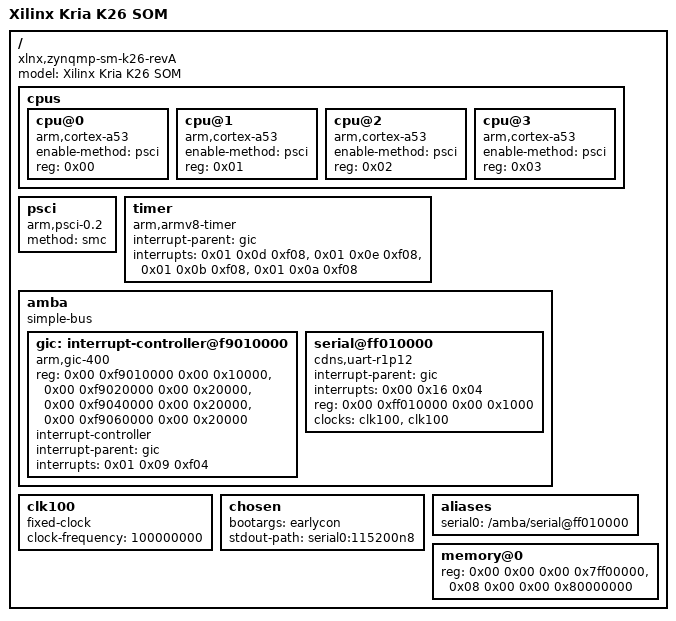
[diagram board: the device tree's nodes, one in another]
/dts-v1/;

/ {
    compatible = "xlnx,zynqmp-sm-k26-revA\0xlnx,zynqmp-sm-k26\0xlnx,zynqmp";
    #address-cells = <0x02>;
    #size-cells = <0x02>;
    model = "Xilinx Kria K26 SOM";

    cpus {
        #address-cells = <0x01>;
        #size-cells = <0x00>;

        cpu@0 {
            compatible = "arm,cortex-a53\0arm,armv8";
            device_type = "cpu";
            enable-method = "psci";
            reg = <0x00>;
        };

        cpu@1 {
            compatible = "arm,cortex-a53\0arm,armv8";
            device_type = "cpu";
            enable-method = "psci";
            reg = <0x01>;
        };

        cpu@2 {
            compatible = "arm,cortex-a53\0arm,armv8";
            device_type = "cpu";
            enable-method = "psci";
            reg = <0x02>;
        };

        cpu@3 {
            compatible = "arm,cortex-a53\0arm,armv8";
            device_type = "cpu";
            enable-method = "psci";
            reg = <0x03>;
        };
    };

    psci {
        compatible = "arm,psci-0.2";
        method = "smc";
    };

    timer {
        compatible = "arm,armv8-timer";
        interrupt-parent = <&gic>;
        interrupts = <0x01 0x0d 0xf08>,
                     <0x01 0x0e 0xf08>,
                     <0x01 0x0b 0xf08>,
                     <0x01 0x0a 0xf08>;
    };

    amba {
        compatible = "simple-bus";
        #address-cells = <0x02>;
        #size-cells = <0x02>;
        ranges;

        gic: interrupt-controller@f9010000 {
            compatible = "arm,gic-400";
            #interrupt-cells = <0x03>;
            reg = <0x00 0xf9010000 0x00 0x10000>,
                  <0x00 0xf9020000 0x00 0x20000>,
                  <0x00 0xf9040000 0x00 0x20000>,
                  <0x00 0xf9060000 0x00 0x20000>;
            interrupt-controller;
            interrupt-parent = <&gic>;
            interrupts = <0x01 0x09 0xf04>;
        };

        serial@ff010000 {
            compatible = "cdns,uart-r1p12\0xlnx,xuartps";
            status = "okay";
            interrupt-parent = <&gic>;
            interrupts = <0x00 0x16 0x04>;
            reg = <0x00 0xff010000 0x00 0x1000>;
            clock-names = "uart_clk\0pclk";
            clocks = <&clk100>, <&clk100>;
        };
    };

    clk100: clk100 {
        compatible = "fixed-clock";
        #clock-cells = <0x00>;
        clock-frequency = <100000000>;
    };

    chosen {
        bootargs = "earlycon";
        stdout-path = "serial0:115200n8";
    };

    aliases {
        serial0 = "/amba/serial@ff010000";
    };

    memory@0 {
        device_type = "memory";
        reg = <0x00 0x00 0x00 0x7ff00000>,
              <0x08 0x00 0x00 0x80000000>;
    };
};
